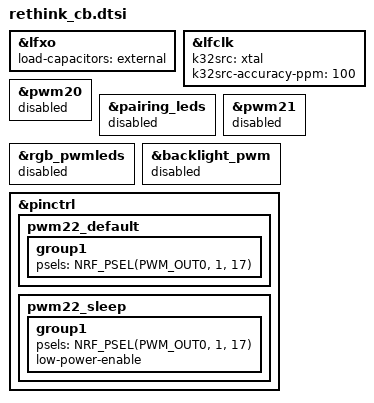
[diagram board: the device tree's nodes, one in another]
/*
 * Copyright (c) 2026 Ziemniaczenka
 * SPDX-License-Identifier: MIT
 *
 * Control Board setup shared by all ReThink shields.
 */

// The 32.768 kHz crystal X1 instead of the RC oscillator framework-cb chose.
// X1 has 12 pF capacitors on the board (C12, C26), so no internal ones;
// Framework's DTS adds 17 pF internal on top, which framework-cb avoided by
// running on the RC. On the RC the system timer (GRTC), which also times the
// Bluetooth link, keeps time from the low-power RC (LFLPRC) while the chip
// sleeps; on battery the hosts' connections then timed out (USB keeps the
// chip awake). The crystal also needs no calibration every 4 s.
&lfxo {
    load-capacitors = "external";
    /delete-property/ load-capacitance-femtofarad;
};

&lfclk {
    k32src = "xtal";
    // The crystal's tolerance plus capacitors not matched to its datasheet:
    // a margin, not a measurement
    k32src-accuracy-ppm = <100>;
};

// White LEDs (src/profile_leds.c) and the RGB LED (framework-cb's
// status_led.c) are driven as GPIOs. With CONFIG_PWM enabled, PWM20/21 would
// take over their pins.
&pwm20 {
    status = "disabled";
};

&pairing_leds {
    status = "disabled";
};

&pwm21 {
    status = "disabled";
};

&rgb_pwmleds {
    status = "disabled";
};

// Framework's backlight PWM on P3.11. On ReThink, P3.11 switches VLED_BL to
// the adapter (rethink,backlight enable-gpios) and PWM22 drives P1.17.
&backlight_pwm {
    status = "disabled";
};

&pinctrl {
    pwm22_default: pwm22_default {
        group1 {
            psels = <NRF_PSEL(PWM_OUT0, 1, 17)>;
        };
    };

    pwm22_sleep: pwm22_sleep {
        group1 {
            psels = <NRF_PSEL(PWM_OUT0, 1, 17)>;
            low-power-enable;
        };
    };
};
